# ISD91200B_v1 register map
File version: 1.0
Registers are 32-bit, read-write, reset 0x0 unless marked. A register's access mark holds for its fields unless they carry their own. Offsets are from the block's base; [hi:lo] are bit positions; lines under a group give offsets from that group; {n}, {i} and the like mark numbered series.

## SYS — SYS Register Map
Base 0x50000000
0x00 SYS_PDID ro reset not defined — Product ID
  [31:0] PDID — Product Identifier. Chip identifier for I91200 series.
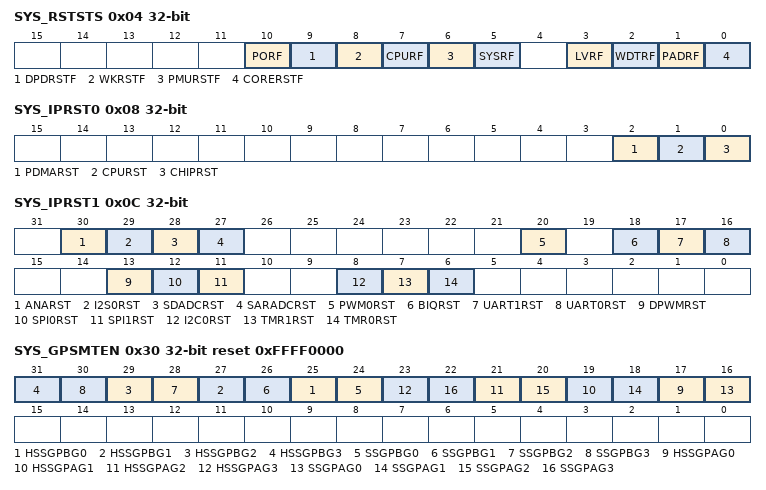
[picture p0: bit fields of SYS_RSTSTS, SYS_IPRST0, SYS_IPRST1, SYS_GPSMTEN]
0x04 SYS_RSTSTS (reset mask 0xFFFFF000) — System Reset Source Register
  [10] PORF — Power on Reset Flag. The PORF flag is set by hardware if device has powered up from a power on reset condition or standby power down. This bit is cleared by writing 1 to itself. Writing 1 to this bit will clear bits PORF, DPDRSTF, and WKRSTF
    0=No detected; 1=A power on Reset has occurred
  [9] DPDRSTF — Deep Power Down Reset Flag. The DPDRSTF flag is set by hardware if device has powered up due to the DPD timer function. This bit is cleared by writing 1 to itself. Writing 1 to this bit will clear bits PORF, DPDRSTF, and WKRSTF
    0=No detected; 1=A power on was triggered by DPD timer
  [8] WKRSTF — Wakeup Pin Reset Flag. The WKRSTF flag is set by hardware if device has powered up from deep power down (DPD) due to action of the WAKEUP pin. This bit is cleared by writing 1 to itself. Writing 1 to this bit will clear bits PORF, DPDRSTF, and WKRSTF
    0=No detected; 1=A power on was triggered by WAKEUP pin
  [7] CPURF — Reset Source From CPU. The CPURF flag is set by hardware if software writes CPURST (SYS_IPRST0[1]) with a "1" to reset Cortex-M0 CPU kernel and Flash memory controller (FMC). This bit is cleared by writing 1 to itself.
    0=No reset from CPU; 1=The Cortex-M0 CPU kernel and FMC has been reset by software setting CPURST to 1
  [6] PMURSTF — Reset Source From PMU. The PMURSTF flag is set if the PMU. This bit is cleared by writing 1 to itself.
    0=No reset from PMU; 1=PMU reset the system from a power down/standby event
  [5] SYSRF — Reset Source From MCU. The SYSRF flag is set if the previous reset source originates from the Cortex_M0 kernel. This bit is cleared by writing 1 to itself.
    0=No reset from MCU; 1=The Cortex_M0 MCU issued a reset signal to reset the system by software writing 1 to bit SYSRESTREQ(SYSINFO_AIRCTL[2], Application Interrupt and Reset Control Register) in system control registers of Cortex_M0 kernel
  [3] LVRF — Low Voltage Reset Flag. The LVRF flag is set if pervious reset source originates from the LVR module. This bit is cleared by writing 1 to itself.
    0=No reset from LVR; 1=The LVR module issued the reset signal to reset the system
  [2] WDTRF — Reset Source From WDT. The WDTRF flag is set if pervious reset source originates from the Watch-Dog module. This bit is cleared by writing 1 to itself.
    0=No reset from Watch-Dog; 1=The Watch-Dog module issued the reset signal to reset the system
  [1] PADRF — The RSTS_PAD Flag Is If Pervious Reset Source Originates From the /RESET Pin. This bit is cleared by writing 1 to itself.
    0=No reset from Pin /RESET; 1=Pin /RESET had issued the reset signal to reset the system
  [0] CORERSTF — Reset Source From CORE. The CORERSTF flag is set if the core has been reset. Possible sources of reset are a Power-On Reset (POR), RESETn Pin Reset or PMU reset. This bit is cleared by writing 1 to itself.
    0=No reset from CORE; 1=Core was reset by hardware block
0x08 SYS_IPRST0 — IP Reset Control Resister0
  [2] PDMARST — PDMA Controller Reset. Set "1" will generate a reset signal to the PDMA Block. User needs to set this bit to "0" to release from the reset state
    0=Normal operation; 1=PDMA IP reset
  [1] CPURST — CPU Kernel One Shot Reset. Setting this bit will reset the CPU kernel and Flash Memory Controller(FMC), this bit will automatically return to "0" after the 2 clock cycles. This bit is a protected bit, to program first issue the unlock sequence
    0=Normal; 1=Reset CPU
  [0] CHIPRST — CHIP One Shot Reset. Set this bit will reset the whole chip, this bit will automatically return to "0" after the 2 clock cycles. CHIPRST has same behavior as POR reset, all the chip modules are reset and the chip configuration settings from flash are reloaded. This bit is a protected bit, to program first issue the unlock sequence
    0=Normal; 1=Reset CHIP
0x0C SYS_IPRST1 — IP Reset Control Resister1
  [30] ANARST — Analog Block Control Reset
    0=Normal Operation; 1=Reset
  [29] I2S0RST — I2S Controller Reset
    0=Normal Operation; 1=Reset
  [28] SDADCRST — SDADC Controller Reset
    0=Normal Operation; 1=Reset
  [27] SARADCRST — SAR ADC Controller Reset,
    0=Normal Operation; 1=Reset,
  [20] PWM0RST — PWM0 Controller Reset
    0=Normal Operation; 1=Reset
  [18] BIQRST — Biquad Filter Block Reset
    0=Normal Operation; 1=Reset
  [17] UART1RST — UART1 Controller Reset
    0=Normal Operation; 1=Reset
  [16] UART0RST — UART0 Controller Reset
    0=Normal Operation; 1=Reset
  [13] DPWMRST — DPWM Speaker Driver Reset
    0=Normal Operation; 1=Reset
  [12] SPI0RST — SPI0 Controller Reset
    0=Normal Operation; 1=Reset
  [11] SPI1RST — SPI1 Controller Reset
    0=Normal Operation; 1=Reset
  [8] I2C0RST — I2C0 Controller Reset
    0=Normal Operation; 1=Reset
  [7] TMR1RST — Timer1 Controller Reset
    0=Normal Operation; 1=Reset
  [6] TMR0RST — Timer0 Controller Reset
    0=Normal Operation; 1=Reset
0x30 SYS_GPSMTEN reset 0xFFFF0000 — GPIOA/B Input Type Control Register
  [2n+25] HSSGPBG{n} (n=0..3) — this Register Controls Whether the GPIO Input Buffer Schmitt Trigger Is Enabled and Whether High or Low Slew Rate Is Selected for Output Dr. Each bit controls a group of four GPIO pins
    0=GPIOB {4n+3}/{4n+2}/{4n+1}/{4n} Output low slew rate; 1=GPIOB {4n+3}/{4n+2}/{4n+1}/{4n} Output high slew rate
  [2n+24] SSGPBG{n} (n=0..3) — this Register Controls Whether the GPIO Input Buffer Schmitt Trigger Is Enabled and Whether High or Low Slew Rate Is Selected for Output Dr. Each bit controls a group of four GPIO pins
    0=GPIOB {4n+3}/{4n+2}/{4n+1}/{4n} input CMOS enabled; 1=GPIOB {4n+3}/{4n+2}/{4n+1}/{4n} input Schmitt Trigger enabled
  [2n+17] HSSGPAG{n} (n=0..3) — this Register Controls Whether the GPIO Input Buffer Schmitt Trigger Is Enabled and Whether High or Low Slew Rate Is Selected for Output Dr. Each bit controls a group of four GPIO pins
    0=GPIOA {4n+3}/{4n+2}/{4n+1}/{4n} Output low slew rate; 1=GPIOA {4n+3}/{4n+2}/{4n+1}/{4n} Output high slew rate
  [2n+16] SSGPAG{n} (n=0..3) — this Register Controls Whether the GPIO Input Buffer Schmitt Trigger Is Enabled and Whether High or Low Slew Rate Is Selected for Output Dr. Each bit controls a group of four GPIO pins
    0=GPIOA {4n+3}/{4n+2}/{4n+1}/{4n} input CMOS enabled; 1=GPIOA {4n+3}/{4n+2}/{4n+1}/{4n} input Schmitt Trigger enabled
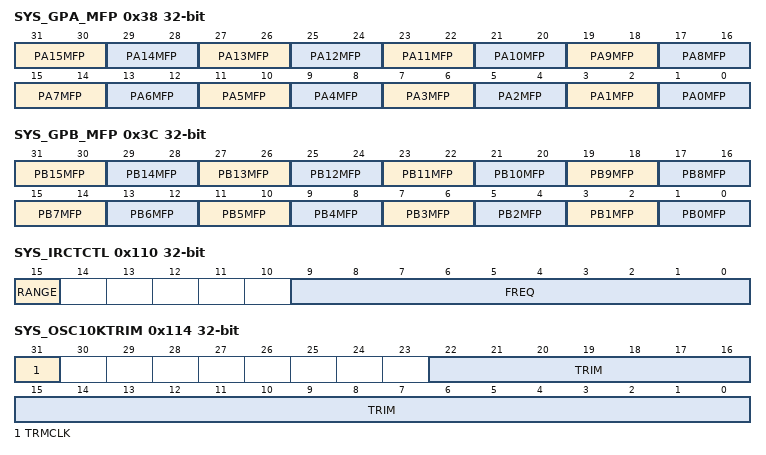
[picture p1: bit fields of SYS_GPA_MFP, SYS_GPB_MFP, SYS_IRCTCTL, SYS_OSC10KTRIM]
0x38 SYS_GPA_MFP — GPIOA Multiple Alternate Functions Control Register
  [31:30] PA15MFP — Alternate Function Setting for PA15MFP
    0=GPIO; 1=UART1_RX; 2=MCLK; 3=X32KO
  [29:28] PA14MFP — Alternate Function Setting for PA14MFP
    0=GPIO; 1=UART1_TX; 2=DMIC_CLK; 3=X32KI
  [27:26] PA13MFP — Alternate Function Setting for PA13MFP
    0=GPIO; 1=PWM0CH3; 2=X12MO; 3=I2C0_SCL
  [25:24] PA12MFP — Alternate Function Setting for PA12MFP
    0=GPIO; 1=PWM0CH2; 2=X12MI; 3=I2C0_SDA
  [23:22] PA11MFP — Alternate Function Setting for PA11MFP
    0=GPIO; 1=PWM0CH1; 2=TM1; 3=DPWM_M
  [21:20] PA10MFP — Alternate Function Setting for PA10MFP
    0=GPIO; 1=PWM0CH0; 2=TM0; 3=DPWM_P
  [19:18] PA9MFP — Alternate Function Setting for PA9MFP
    0=GPIO; 1=I2C0_SCL; 2=UART1_RX; 3=UART0_CTSn
  [17:16] PA8MFP — Alternate Function Setting for PA8MFP
    0=GPIO; 1=I2C0_SDA; 2=UART1_TX; 3=UART0_RTSn
  [15:14] PA7MFP — Alternate Function Setting for PA7MFP
    0=GPIO; 1=UART0_RX; 2=I2C0_SCL; 3=SPI1_MISO
  [13:12] PA6MFP — Alternate Function Setting for PA6MFP
    0=GPIO; 1=UART0_TX; 2=I2C0_SDA; 3=SPI1_SSB
  [11:10] PA5MFP — Alternate Function Setting for PA5MFP
    0=GPIO; 1=SPI0_MOSI1; 2=UART0_RX; 3=SPI1_SCLK
  [9:8] PA4MFP — Alternate Function Setting for PA4MFP
    0=GPIO; 1=SPI0_MISO0; 2=UART0_TX; 3=SPI1_MOSI
  [7:6] PA3MFP — Alternate Function Setting for PA3MFP
    0=GPIO; 1=SPI0_SSB0; 2=SARADC_TRIG; 3=I2S0_SDO
  [5:4] PA2MFP — Alternate Function Setting for PA2MFP
    0=GPIO; 1=SPI0_SCLK0; 2=DMIC_DAT; 3=I2S0_SDI
  [3:2] PA1MFP — Alternate Function Setting for PA1MFP
    0=GPIO; 1=SPI0_MOSI0; 3=I2S0_BCLK
  [1:0] PA0MFP — Alternate Function Setting for PA0MFP
    0=GPIO; 1=SPI0_MISO1; 3=I2S0_FS
0x3C SYS_GPB_MFP — GPIOB Multiple Alternate Functions Control Register
  [31:30] PB15MFP — Alternate Function Setting for PB15MFP
    0=GPIO; 1=SPI0_SSB0; 2=SPI1_MISO; 3=MCLK
  [29:28] PB14MFP — Alternate Function Setting for PB14MFP
    0=GPIO; 1=SPI0_SCLK0; 2=SPI1_SSB; 3=DMIC_CLK
  [27:26] PB13MFP — Alternate Function Setting for PB13MFP
    0=GPIO; 1=SPI0_MOSI0; 2=SPI1_SCLK; 3=SARADC_TRIG
  [25:24] PB12MFP — Alternate Function Setting for PB12MFP
    0=GPIO; 1=SP0_MISO1; 2=SPI1_MOSI; 3=DMIC_DAT
  [23:22] PB11MFP — Alternate Function Setting for PB11MFP
    0=GPIO; 2=I2S0_SDO; 3=UART1_RX
  [21:20] PB10MFP — Alternate Function Setting for PB10MFP
    0=GPIO; 2=I2S0_SDI; 3=UART1_TX
  [19:18] PB9MFP — Alternate Function Setting for PB9MFP
    0=GPIO; 1=I2C0_SCL; 2=I2S0_BCLK; 3=UART1_CTsn
  [17:16] PB8MFP — Alternate Function Setting for PB8MFP
    0=GPIO; 1=I2C0_SDA; 2=I2S0_FS; 3=UART1_RSTn
  [15:14] PB7MFP — Alternate Function Setting for PB7MFP
    0=GPIO; 1=I2S0_SDO
  [13:12] PB6MFP — Alternate Function Setting for PB6MFP
    0=GPIO; 1=I2S0_SDI
  [11:10] PB5MFP — Alternate Function Setting for PB5MFP
    0=GPIO; 1=I2S0_BCLK
  [9:8] PB4MFP — Alternate Function Setting for PB4MFP
    0=GPIO; 1=I2S0_FS
  [7:6] PB3MFP — Alternate Function Setting for PB3MFP
    0=GPIO; 1=SPI1_MISO
  [5:4] PB2MFP — Alternate Function Setting for PB2MFP
    0=GPIO; 1=SPI1_SSB
  [3:2] PB1MFP — Alternate Function Setting for PB1MFP
    0=GPIO; 1=SPI1_SCLK
  [1:0] PB0MFP — Alternate Function Setting for PB0MFP
    0=GPIO; 1=SPI1_MOSI
0x54 SYS_WKCTL reset 0x6 — WAKEUP pin control register
0x100 SYS_REGLCTL — Register Lock Control
  [0] REGLCTL — Protected Register Unlock Register
    0=Protected registers are locked. Any write to the target register is ignored; 1=Protected registers are unlocked
0x110 SYS_IRCTCTL reset not defined — Oscillator Frequency Adjustment Control Register
  [15] RANGE — 1: Low Frequency mode of oscillator active (2MHz). 0: High frequency mode (20-50MHz)
  [9:0] FREQ — Current oscillator frequency trim value. (based on CLK_CLKSEL0.HIRCFSEL)
0x114 SYS_OSC10KTRIM reset not defined — 10kHz Oscillator (LIRC) Trim Register
  [31] TRMCLK
  [22:0] TRIM — 23bit trim for LIRC.
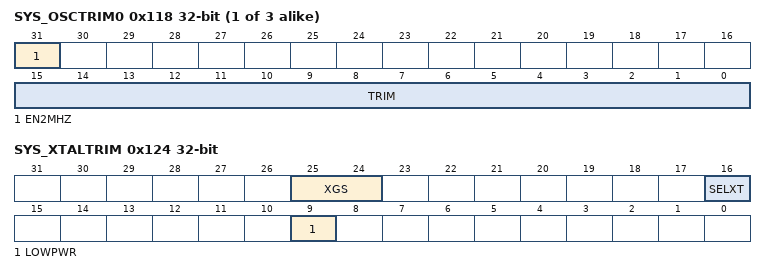
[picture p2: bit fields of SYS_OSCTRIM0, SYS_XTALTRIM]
{0x118+4i} SYS_OSCTRIM{i} reset not defined (i=0..2) — Internal Oscillator Trim Register {i}
  [31] EN2MHZ — 1: Low Frequency mode of oscillator active (2MHz). 0: High frequency mode (20-50MHz)
  [15:0] TRIM — 16bit sign extended representation of 10bit trim.
0x124 SYS_XTALTRIM reset not defined — External Crystal Oscillator Trim Register
  [25:24] XGS — HXT Gain Select
  [16] SELXT — HXT select external clock. 0: Disable. 1: Enable
  [9] LOWPWR — 1: low power mode. 0: normal mode.
